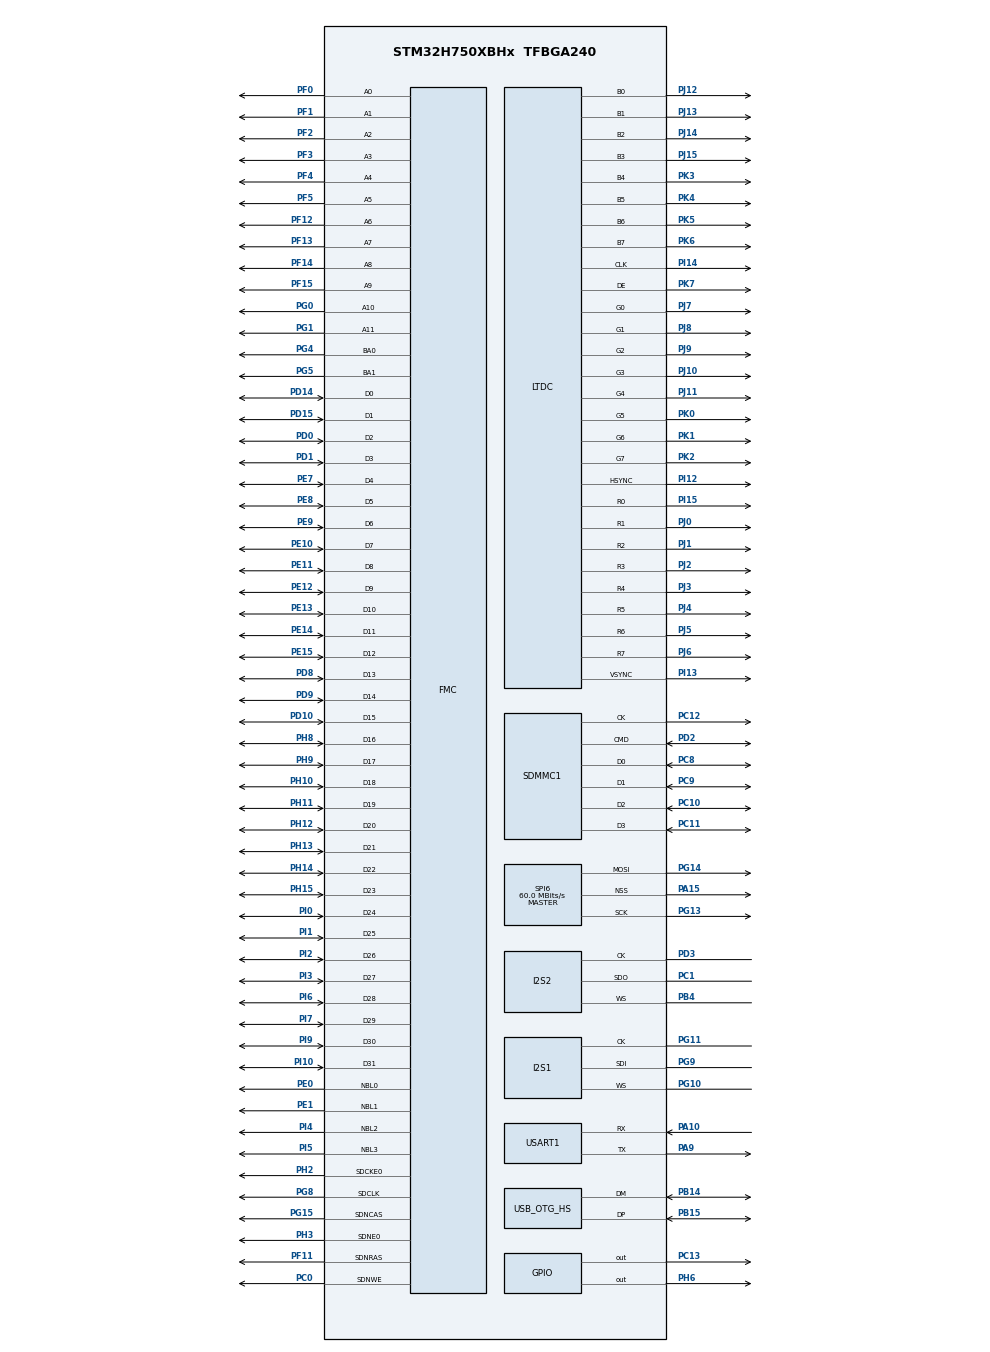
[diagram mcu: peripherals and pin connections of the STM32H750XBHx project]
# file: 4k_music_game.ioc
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CORTEX_M7.AccessPermission-Cortex_Memory_Protection_Unit_Region0_Settings=MPU_REGION_FULL_ACCESS
CORTEX_M7.AccessPermission_S-Cortex_Memory_Protection_Unit_Region1_Settings_S=MPU_REGION_FULL_ACCESS
CORTEX_M7.AccessPermission_Spec=MPU_REGION_FULL_ACCESS
CORTEX_M7.BaseAddress-Cortex_Memory_Protection_Unit_Region0_Settings=0xC0000000
CORTEX_M7.BaseAddress_S-Cortex_Memory_Protection_Unit_Region1_Settings_S=0x90000000
CORTEX_M7.BaseAddress_Spec=0xC0000000
CORTEX_M7.CPU_DCache=Enabled
CORTEX_M7.CPU_ICache=Enabled
CORTEX_M7.DisableExec_Spec=MPU_INSTRUCTION_ACCESS_ENABLE
CORTEX_M7.Enable-Cortex_Memory_Protection_Unit_Region0_Settings=MPU_REGION_ENABLE
CORTEX_M7.Enable_S-Cortex_Memory_Protection_Unit_Region1_Settings_S=MPU_REGION_ENABLE
CORTEX_M7.Enable_Spec=MPU_REGION_ENABLE
CORTEX_M7.IsBufferable-Cortex_Memory_Protection_Unit_Region0_Settings=MPU_ACCESS_BUFFERABLE
CORTEX_M7.IsBufferable_Spec=MPU_ACCESS_NOT_BUFFERABLE
CORTEX_M7.IsCacheable-Cortex_Memory_Protection_Unit_Region0_Settings=MPU_ACCESS_CACHEABLE
CORTEX_M7.IsCacheable_S-Cortex_Memory_Protection_Unit_Region1_Settings_S=MPU_ACCESS_CACHEABLE
CORTEX_M7.IsCacheable_Spec=MPU_ACCESS_CACHEABLE
CORTEX_M7.IsShareable_Spec=MPU_ACCESS_NOT_SHAREABLE
CORTEX_M7.MPU_Control=MPU_PRIVILEGED_DEFAULT
CORTEX_M7.Size-Cortex_Memory_Protection_Unit_Region0_Settings=MPU_REGION_SIZE_16MB
CORTEX_M7.Size_S-Cortex_Memory_Protection_Unit_Region1_Settings_S=MPU_REGION_SIZE_32MB
CORTEX_M7.Size_Spec=MPU_REGION_SIZE_16MB
CORTEX_M7.SubRegionDisable_Spec=0x0
CORTEX_M7.default_mode_Activation=1
DMA2D.ColorMode=DMA2D_OUTPUT_RGB565
DMA2D.Mode=DMA2D_M2M
Dma.Request0=SPI1_RX
Dma.Request1=SPI2_TX
Dma.SPI1_RX.0.Direction=DMA_PERIPH_TO_MEMORY
Dma.SPI1_RX.0.EventEnable=DISABLE
Dma.SPI1_RX.0.FIFOMode=DMA_FIFOMODE_DISABLE
Dma.SPI1_RX.0.Instance=DMA1_Stream0
Dma.SPI1_RX.0.MemDataAlignment=DMA_MDATAALIGN_WORD
Dma.SPI1_RX.0.MemInc=DMA_MINC_ENABLE
Dma.SPI1_RX.0.Mode=DMA_CIRCULAR
Dma.SPI1_RX.0.PeriphDataAlignment=DMA_PDATAALIGN_WORD
Dma.SPI1_RX.0.PeriphInc=DMA_PINC_DISABLE
Dma.SPI1_RX.0.Polarity=HAL_DMAMUX_REQ_GEN_RISING
Dma.SPI1_RX.0.Priority=DMA_PRIORITY_HIGH
Dma.SPI1_RX.0.RequestNumber=1
Dma.SPI1_RX.0.SignalID=NONE
Dma.SPI1_RX.0.SyncEnable=DISABLE
Dma.SPI1_RX.0.SyncPolarity=HAL_DMAMUX_SYNC_NO_EVENT
Dma.SPI1_RX.0.SyncRequestNumber=1
Dma.SPI1_RX.0.SyncSignalID=NONE
Dma.SPI2_TX.1.Direction=DMA_MEMORY_TO_PERIPH
Dma.SPI2_TX.1.EventEnable=DISABLE
Dma.SPI2_TX.1.FIFOMode=DMA_FIFOMODE_DISABLE
Dma.SPI2_TX.1.Instance=DMA1_Stream1
Dma.SPI2_TX.1.MemDataAlignment=DMA_MDATAALIGN_HALFWORD
Dma.SPI2_TX.1.MemInc=DMA_MINC_ENABLE
Dma.SPI2_TX.1.Mode=DMA_CIRCULAR
Dma.SPI2_TX.1.PeriphDataAlignment=DMA_PDATAALIGN_HALFWORD
Dma.SPI2_TX.1.PeriphInc=DMA_PINC_DISABLE
Dma.SPI2_TX.1.Polarity=HAL_DMAMUX_REQ_GEN_RISING
Dma.SPI2_TX.1.Priority=DMA_PRIORITY_LOW
Dma.SPI2_TX.1.RequestNumber=1
Dma.SPI2_TX.1.SignalID=NONE
Dma.SPI2_TX.1.SyncEnable=DISABLE
Dma.SPI2_TX.1.SyncPolarity=HAL_DMAMUX_SYNC_NO_EVENT
Dma.SPI2_TX.1.SyncRequestNumber=1
Dma.SPI2_TX.1.SyncSignalID=NONE
FMC.CASLatency1=FMC_SDRAM_CAS_LATENCY_3
FMC.ExitSelfRefreshDelay1=7
FMC.LoadToActiveDelay1=2
FMC.RCDDelay1=2
FMC.RPDelay1=2
FMC.RPDelay2=2
FMC.ReadBurst1=FMC_SDRAM_RBURST_ENABLE
FMC.ReadBurst2=FMC_SDRAM_RBURST_ENABLE
FMC.RowCycleDelay1=7
FMC.RowCycleDelay2=7
FMC.SDClockPeriod1=FMC_SDRAM_CLOCK_PERIOD_2
FMC.SDClockPeriod2=FMC_SDRAM_CLOCK_PERIOD_2
FMC.SelfRefreshTime1=4
FMC.WriteRecoveryTime1=3
FREERTOS.Tasks01=defaultTask,24,256,StartDefaultTask,Default,NULL,Dynamic,NULL,NULL
FREERTOS.configCHECK_FOR_STACK_OVERFLOW=2
FREERTOS.configENABLE_FPU=1
FREERTOS.configGENERATE_RUN_TIME_STATS=1
FREERTOS.configTOTAL_HEAP_SIZE=256000
FREERTOS.configUSE_STATS_FORMATTING_FUNCTIONS=1
FREERTOS.configUSE_TICK_HOOK=1
I2S1.AudioFreq=I2S_AUDIOFREQ_32K
I2S1.Data24BitAlignment=I2S_DATA_24BIT_ALIGNMENT_RIGHT
I2S1.DataFormat=I2S_DATAFORMAT_24B
I2S1.ErrorAudioFreq=-0.26 %
I2S1.Instance=SPI$Index
I2S1.RealAudioFreq=31.914 KHz
I2S2.AudioFreq=I2S_AUDIOFREQ_44K
I2S2.ErrorAudioFreq=0.26 %
I2S2.Instance=SPI$Index
I2S2.RealAudioFreq=44.117 KHz
JPEG.JPEG_RGB_FORMAT=JPEG_RGB565
LTDC.ActiveW=800
LTDC.Alpha0_L0=0
LTDC.Alpha0_L1=122
LTDC.Alpha_L0=255
LTDC.FBStartAdress_L0=0xC0000000
LTDC.Green_L0=255
LTDC.HBP=80
LTDC.HFP=200
LTDC.HSync=1
LTDC.ImageHeight_L0=480
LTDC.ImageWidth_L0=800
LTDC.Layers=0
LTDC.PixelFormat_L0=LTDC_PIXEL_FORMAT_RGB565
LTDC.Red_L1=255
LTDC.VBP=40
LTDC.VFP=22
LTDC.VSync=1
LTDC.WindowX1_L0=800
LTDC.WindowX1_L1=800
LTDC.WindowY1_L0=480
LTDC.WindowY1_L1=480
Mcu.Family=STM32H7
Mcu.Name=STM32H750XBHx
Mcu.Package=TFBGA240
Mdma.MDMA_Channel6.JPEG_OUTFIFO_TH.0.BlockCount=0
Mdma.MDMA_Channel6.JPEG_OUTFIFO_TH.0.BlockDataLength=0
Mdma.MDMA_Channel6.JPEG_OUTFIFO_TH.0.BufferTransferLength=32
Mdma.MDMA_Channel6.JPEG_OUTFIFO_TH.0.CircularMode=MDMA_LINEAR_LIST
Mdma.MDMA_Channel6.JPEG_OUTFIFO_TH.0.DataAlignment=MDMA_DATAALIGN_PACKENABLE
Mdma.MDMA_Channel6.JPEG_OUTFIFO_TH.0.DestBlockAddressOffset=0
Mdma.MDMA_Channel6.JPEG_OUTFIFO_TH.0.DestBurst=MDMA_DEST_BURST_32BEATS
Mdma.MDMA_Channel6.JPEG_OUTFIFO_TH.0.DestDataSize=MDMA_DEST_DATASIZE_WORD
Mdma.MDMA_Channel6.JPEG_OUTFIFO_TH.0.DestinationInc=MDMA_DEST_INC_WORD
Mdma.MDMA_Channel6.JPEG_OUTFIFO_TH.0.DstAddress=0
Mdma.MDMA_Channel6.JPEG_OUTFIFO_TH.0.Endianness=MDMA_LITTLE_ENDIANNESS_PRESERVE
Mdma.MDMA_Channel6.JPEG_OUTFIFO_TH.0.Instance=MDMA_Channel6
Mdma.MDMA_Channel6.JPEG_OUTFIFO_TH.0.MaskAddress=0
Mdma.MDMA_Channel6.JPEG_OUTFIFO_TH.0.MaskData=0
Mdma.MDMA_Channel6.JPEG_OUTFIFO_TH.0.Priority=MDMA_PRIORITY_VERY_HIGH
Mdma.MDMA_Channel6.JPEG_OUTFIFO_TH.0.Rank=First
Mdma.MDMA_Channel6.JPEG_OUTFIFO_TH.0.SourceBlockAddressOffset=0
Mdma.MDMA_Channel6.JPEG_OUTFIFO_TH.0.SourceBurst=MDMA_SOURCE_BURST_32BEATS
Mdma.MDMA_Channel6.JPEG_OUTFIFO_TH.0.SourceDataSize=MDMA_SRC_DATASIZE_WORD
Mdma.MDMA_Channel6.JPEG_OUTFIFO_TH.0.SourceInc=MDMA_SRC_INC_DISABLE
Mdma.MDMA_Channel6.JPEG_OUTFIFO_TH.0.SrcAddress=0
Mdma.MDMA_Channel6.JPEG_OUTFIFO_TH.0.TransferTriggerMode=MDMA_BUFFER_TRANSFER
Mdma.MDMA_Channel6.Request0=JPEG_OUTFIFO_TH
Mdma.MDMA_Channel6.RequestsNb=1
Mdma.MDMA_Channel7.JPEG_INFIFO_TH.0.BlockCount=0
Mdma.MDMA_Channel7.JPEG_INFIFO_TH.0.BlockDataLength=0
Mdma.MDMA_Channel7.JPEG_INFIFO_TH.0.BufferTransferLength=32
Mdma.MDMA_Channel7.JPEG_INFIFO_TH.0.CircularMode=MDMA_LINEAR_LIST
Mdma.MDMA_Channel7.JPEG_INFIFO_TH.0.DataAlignment=MDMA_DATAALIGN_PACKENABLE
Mdma.MDMA_Channel7.JPEG_INFIFO_TH.0.DestBlockAddressOffset=0
Mdma.MDMA_Channel7.JPEG_INFIFO_TH.0.DestBurst=MDMA_DEST_BURST_32BEATS
Mdma.MDMA_Channel7.JPEG_INFIFO_TH.0.DestDataSize=MDMA_DEST_DATASIZE_WORD
Mdma.MDMA_Channel7.JPEG_INFIFO_TH.0.DestinationInc=MDMA_DEST_INC_DISABLE
Mdma.MDMA_Channel7.JPEG_INFIFO_TH.0.DstAddress=0
Mdma.MDMA_Channel7.JPEG_INFIFO_TH.0.Endianness=MDMA_LITTLE_ENDIANNESS_PRESERVE
Mdma.MDMA_Channel7.JPEG_INFIFO_TH.0.Instance=MDMA_Channel7
Mdma.MDMA_Channel7.JPEG_INFIFO_TH.0.MaskAddress=0
Mdma.MDMA_Channel7.JPEG_INFIFO_TH.0.MaskData=0
Mdma.MDMA_Channel7.JPEG_INFIFO_TH.0.Priority=MDMA_PRIORITY_HIGH
Mdma.MDMA_Channel7.JPEG_INFIFO_TH.0.Rank=First
Mdma.MDMA_Channel7.JPEG_INFIFO_TH.0.SourceBlockAddressOffset=0
Mdma.MDMA_Channel7.JPEG_INFIFO_TH.0.SourceBurst=MDMA_SOURCE_BURST_32BEATS
Mdma.MDMA_Channel7.JPEG_INFIFO_TH.0.SourceDataSize=MDMA_SRC_DATASIZE_WORD
Mdma.MDMA_Channel7.JPEG_INFIFO_TH.0.SourceInc=MDMA_SRC_INC_WORD
Mdma.MDMA_Channel7.JPEG_INFIFO_TH.0.SrcAddress=0
Mdma.MDMA_Channel7.JPEG_INFIFO_TH.0.TransferTriggerMode=MDMA_BUFFER_TRANSFER
Mdma.MDMA_Channel7.Request0=JPEG_INFIFO_TH
Mdma.MDMA_Channel7.RequestsNb=1
Mdma.RequestSet0=MDMA_Channel7
Mdma.RequestSet1=MDMA_Channel6
Mdma.RequestSetsNb=2
NVIC.DMA1_Stream0_IRQn=true\:5\:0\:false\:false\:true\:true\:false\:true\:true
NVIC.DMA1_Stream1_IRQn=true\:5\:0\:false\:false\:true\:true\:false\:true\:true
NVIC.JPEG_IRQn=true\:5\:0\:false\:false\:true\:true\:true\:true\:true
NVIC.LTDC_ER_IRQn=true\:5\:0\:false\:false\:true\:true\:true\:true\:true
NVIC.LTDC_IRQn=true\:5\:0\:false\:false\:true\:true\:true\:true\:true
NVIC.MDMA_IRQn=true\:5\:0\:false\:false\:true\:true\:false\:true\:true
NVIC.OTG_HS_EP1_IN_IRQn=true\:5\:0\:false\:false\:true\:true\:true\:true\:true
NVIC.OTG_HS_EP1_OUT_IRQn=true\:5\:0\:false\:false\:true\:true\:true\:true\:true
NVIC.OTG_HS_IRQn=true\:5\:0\:false\:false\:true\:true\:true\:true\:true
NVIC.PriorityGroup=NVIC_PRIORITYGROUP_4
NVIC.SDMMC1_IRQn=true\:5\:0\:false\:false\:true\:true\:true\:true\:true
NVIC.TIM17_IRQn=true\:15\:0\:false\:false\:true\:false\:false\:true\:true
NVIC.TimeBase=TIM17_IRQn
NVIC.TimeBaseIP=TIM17
PA10.GPIO_Speed=GPIO_SPEED_FREQ_VERY_HIGH
PA10.Mode=Asynchronous
PA10.Signal=USART1_RX
PA13\ (JTMS/SWDIO).Mode=Serial_Wire
PA13\ (JTMS/SWDIO).Signal=DEBUG_JTMS-SWDIO
PA14\ (JTCK/SWCLK).Mode=Serial_Wire
PA14\ (JTCK/SWCLK).Signal=DEBUG_JTCK-SWCLK
PA15\ (JTDI).GPIO_Speed=GPIO_SPEED_FREQ_VERY_HIGH
PA15\ (JTDI).Mode=NSS_Signal_Hard_Output
PA15\ (JTDI).Signal=SPI6_NSS
PA9.GPIO_Speed=GPIO_SPEED_FREQ_VERY_HIGH
PA9.Mode=Asynchronous
PA9.Signal=USART1_TX
PB14.GPIO_Speed=GPIO_SPEED_FREQ_VERY_HIGH
PB14.Mode=Host_FS
PB14.Signal=USB_OTG_HS_DM
PB15.GPIO_Speed=GPIO_SPEED_FREQ_VERY_HIGH
PB15.Mode=Host_FS
PB15.Signal=USB_OTG_HS_DP
PB4\ (NJTRST).GPIO_Speed=GPIO_SPEED_FREQ_VERY_HIGH
PB4\ (NJTRST).Mode=Half_Duplex_Master_Tx
PB4\ (NJTRST).Signal=I2S2_WS
PC0.Signal=FMC_SDNWE
PC1.GPIO_Speed=GPIO_SPEED_FREQ_VERY_HIGH
PC1.Mode=Half_Duplex_Master_Tx
PC1.Signal=I2S2_SDO
PC10.Mode=SD_4_bits_Wide_bus
PC10.Signal=SDMMC1_D2
PC11.Mode=SD_4_bits_Wide_bus
PC11.Signal=SDMMC1_D3
PC12.Mode=SD_4_bits_Wide_bus
PC12.Signal=SDMMC1_CK
PC13.Signal=GPIO_Output
PC14-OSC32_IN\ (OSC32_IN).Mode=LSE-External-Oscillator
PC14-OSC32_IN\ (OSC32_IN).Signal=RCC_OSC32_IN
PC15-OSC32_OUT\ (OSC32_OUT).Mode=LSE-External-Oscillator
PC15-OSC32_OUT\ (OSC32_OUT).Signal=RCC_OSC32_OUT
PC8.Mode=SD_4_bits_Wide_bus
PC8.Signal=SDMMC1_D0
PC9.Mode=SD_4_bits_Wide_bus
PC9.Signal=SDMMC1_D1
PD0.Signal=FMC_D2_DA2
PD1.Signal=FMC_D3_DA3
PD10.Signal=FMC_D15_DA15
PD14.Signal=FMC_D0_DA0
PD15.Signal=FMC_D1_DA1
PD2.Mode=SD_4_bits_Wide_bus
PD2.Signal=SDMMC1_CMD
PD3.GPIO_Speed=GPIO_SPEED_FREQ_VERY_HIGH
PD3.Mode=Half_Duplex_Master_Tx
PD3.Signal=I2S2_CK
PD8.Signal=FMC_D13_DA13
PD9.Signal=FMC_D14_DA14
PE0.Signal=FMC_NBL0
PE1.Signal=FMC_NBL1
PE10.Signal=FMC_D7_DA7
PE11.Signal=FMC_D8_DA8
PE12.Signal=FMC_D9_DA9
PE13.Signal=FMC_D10_DA10
PE14.Signal=FMC_D11_DA11
PE15.Signal=FMC_D12_DA12
PE7.Signal=FMC_D4_DA4
PE8.Signal=FMC_D5_DA5
PE9.Signal=FMC_D6_DA6
PF0.Signal=FMC_A0
PF1.Signal=FMC_A1
PF11.Signal=FMC_SDNRAS
PF12.Signal=FMC_A6
PF13.Signal=FMC_A7
PF14.Signal=FMC_A8
PF15.Signal=FMC_A9
PF2.Signal=FMC_A2
PF3.Signal=FMC_A3
PF4.Signal=FMC_A4
PF5.Signal=FMC_A5
PG0.Signal=FMC_A10
PG1.Signal=FMC_A11
PG10.GPIO_Speed=GPIO_SPEED_FREQ_VERY_HIGH
PG10.Mode=Half_Duplex_Master_Rx
PG10.Signal=I2S1_WS
PG11.GPIO_Speed=GPIO_SPEED_FREQ_VERY_HIGH
PG11.Mode=Half_Duplex_Master_Rx
PG11.Signal=I2S1_CK
PG13.GPIO_Speed=GPIO_SPEED_FREQ_VERY_HIGH
PG13.Mode=TX_Only_Simplex_Unidirect_Master
PG13.Signal=SPI6_SCK
PG14.GPIO_Speed=GPIO_SPEED_FREQ_VERY_HIGH
PG14.Mode=TX_Only_Simplex_Unidirect_Master
PG14.Signal=SPI6_MOSI
PG15.Signal=FMC_SDNCAS
PG4.Signal=FMC_A14_BA0
PG5.Signal=FMC_A15_BA1
PG8.Signal=FMC_SDCLK
PG9.GPIO_Speed=GPIO_SPEED_FREQ_VERY_HIGH
PG9.Mode=Half_Duplex_Master_Rx
PG9.Signal=I2S1_SDI
PH0-OSC_IN\ (PH0).Mode=HSE-External-Oscillator
PH0-OSC_IN\ (PH0).Signal=RCC_OSC_IN
PH1-OSC_OUT\ (PH1).Mode=HSE-External-Oscillator
PH1-OSC_OUT\ (PH1).Signal=RCC_OSC_OUT
PH10.Signal=FMC_D18
PH11.Signal=FMC_D19
PH12.Signal=FMC_D20
PH13.Signal=FMC_D21
PH14.Signal=FMC_D22
PH15.Signal=FMC_D23
PH2.Mode=SdramChipSelect1_1
PH2.Signal=FMC_SDCKE0
PH3.Mode=SdramChipSelect1_1
PH3.Signal=FMC_SDNE0
PH6.PinState=GPIO_PIN_SET
PH6.Signal=GPIO_Output
PH8.Signal=FMC_D16
PH9.Signal=FMC_D17
PI0.Signal=FMC_D24
PI1.Signal=FMC_D25
PI10.Signal=FMC_D31
PI12.GPIO_Speed=GPIO_SPEED_FREQ_VERY_HIGH
PI12.Mode=RGB888
PI12.Signal=LTDC_HSYNC
PI13.GPIO_Speed=GPIO_SPEED_FREQ_VERY_HIGH
PI13.Mode=RGB888
PI13.Signal=LTDC_VSYNC
PI14.GPIO_Speed=GPIO_SPEED_FREQ_VERY_HIGH
PI14.Mode=RGB888
PI14.Signal=LTDC_CLK
PI15.GPIO_Speed=GPIO_SPEED_FREQ_VERY_HIGH
PI15.Mode=RGB888
PI15.Signal=LTDC_R0
PI2.Signal=FMC_D26
PI3.Signal=FMC_D27
PI4.Signal=FMC_NBL2
PI5.Signal=FMC_NBL3
PI6.Signal=FMC_D28
PI7.Signal=FMC_D29
PI9.Signal=FMC_D30
PJ0.GPIO_Speed=GPIO_SPEED_FREQ_VERY_HIGH
PJ0.Mode=RGB888
PJ0.Signal=LTDC_R1
PJ1.GPIO_Speed=GPIO_SPEED_FREQ_VERY_HIGH
PJ1.Mode=RGB888
PJ1.Signal=LTDC_R2
PJ10.GPIO_Speed=GPIO_SPEED_FREQ_VERY_HIGH
PJ10.Mode=RGB888
PJ10.Signal=LTDC_G3
PJ11.GPIO_Speed=GPIO_SPEED_FREQ_VERY_HIGH
PJ11.Mode=RGB888
PJ11.Signal=LTDC_G4
PJ12.GPIO_Speed=GPIO_SPEED_FREQ_VERY_HIGH
PJ12.Mode=RGB888
PJ12.Signal=LTDC_B0
PJ13.GPIO_Speed=GPIO_SPEED_FREQ_VERY_HIGH
PJ13.Mode=RGB888
PJ13.Signal=LTDC_B1
PJ14.GPIO_Speed=GPIO_SPEED_FREQ_VERY_HIGH
PJ14.Mode=RGB888
PJ14.Signal=LTDC_B2
PJ15.GPIO_Speed=GPIO_SPEED_FREQ_VERY_HIGH
PJ15.Mode=RGB888
PJ15.Signal=LTDC_B3
PJ2.GPIO_Speed=GPIO_SPEED_FREQ_VERY_HIGH
PJ2.Mode=RGB888
PJ2.Signal=LTDC_R3
PJ3.GPIO_Speed=GPIO_SPEED_FREQ_VERY_HIGH
PJ3.Mode=RGB888
PJ3.Signal=LTDC_R4
PJ4.GPIO_Speed=GPIO_SPEED_FREQ_VERY_HIGH
PJ4.Mode=RGB888
PJ4.Signal=LTDC_R5
PJ5.GPIO_Speed=GPIO_SPEED_FREQ_VERY_HIGH
PJ5.Mode=RGB888
PJ5.Signal=LTDC_R6
PJ6.GPIO_Speed=GPIO_SPEED_FREQ_VERY_HIGH
PJ6.Mode=RGB888
PJ6.Signal=LTDC_R7
PJ7.GPIO_Speed=GPIO_SPEED_FREQ_VERY_HIGH
PJ7.Mode=RGB888
PJ7.Signal=LTDC_G0
PJ8.GPIO_Speed=GPIO_SPEED_FREQ_VERY_HIGH
PJ8.Mode=RGB888
PJ8.Signal=LTDC_G1
PJ9.GPIO_Speed=GPIO_SPEED_FREQ_VERY_HIGH
PJ9.Mode=RGB888
PJ9.Signal=LTDC_G2
PK0.GPIO_Speed=GPIO_SPEED_FREQ_VERY_HIGH
PK0.Mode=RGB888
PK0.Signal=LTDC_G5
PK1.GPIO_Speed=GPIO_SPEED_FREQ_VERY_HIGH
PK1.Mode=RGB888
PK1.Signal=LTDC_G6
PK2.GPIO_Speed=GPIO_SPEED_FREQ_VERY_HIGH
PK2.Mode=RGB888
PK2.Signal=LTDC_G7
PK3.GPIO_Speed=GPIO_SPEED_FREQ_VERY_HIGH
PK3.Mode=RGB888
PK3.Signal=LTDC_B4
PK4.GPIO_Speed=GPIO_SPEED_FREQ_VERY_HIGH
PK4.Mode=RGB888
PK4.Signal=LTDC_B5
PK5.GPIO_Speed=GPIO_SPEED_FREQ_VERY_HIGH
PK5.Mode=RGB888
PK5.Signal=LTDC_B6
PK6.GPIO_Speed=GPIO_SPEED_FREQ_VERY_HIGH
PK6.Mode=RGB888
PK6.Signal=LTDC_B7
PK7.GPIO_Speed=GPIO_SPEED_FREQ_VERY_HIGH
PK7.Mode=RGB888
PK7.Signal=LTDC_DE
ProjectManager.HeapSize=0x1000
ProjectManager.StackSize=0x1000
ProjectManager.TargetToolchain=CMake
RCC.ADCFreq_Value=275000000
RCC.APB1Freq_Value=120000000
RCC.APB2Freq_Value=120000000
RCC.APB3Freq_Value=120000000
RCC.APB4Freq_Value=120000000
RCC.CKPERSourceSelection=RCC_CLKPSOURCE_HSE
RCC.CortexFreq_Value=480000000
RCC.D1PPRE=RCC_APB3_DIV2
RCC.D2PPRE1=RCC_APB1_DIV2
RCC.D2PPRE2=RCC_APB2_DIV2
RCC.D3PPRE=RCC_APB4_DIV2
RCC.DIVM1=5
RCC.DIVM2=5
RCC.DIVM3=1
RCC.DIVN1=192
RCC.DIVN2=110
RCC.DIVN3=6
RCC.DIVQ1=5
RCC.DIVR3=5
RCC.HCLKFreq_Value=240000000
RCC.HPRE=RCC_HCLK_DIV2
RCC.PLL2FRACN=0
RCC.PLL3FRACN=0
RCC.PLLFRACN=0
RCC.PLLSourceVirtual=RCC_PLLSOURCE_HSE
RCC.SYSCLKFreq_VALUE=480000000
RCC.SYSCLKSource=RCC_SYSCLKSOURCE_PLLCLK
RCC.USBCLockSelection=RCC_USBCLKSOURCE_HSI48
RCC.USBFreq_Value=48000000
SDMMC1.ClockDiv=6
SDMMC1.HardwareFlowControl=SDMMC_HARDWARE_FLOW_CONTROL_ENABLE
SH.FMC_A0.0=FMC_A0,12b-sda1
SH.FMC_A1.0=FMC_A1,12b-sda1
SH.FMC_A10.0=FMC_A10,12b-sda1
SH.FMC_A11.0=FMC_A11,12b-sda1
SH.FMC_A14_BA0.0=FMC_BA0,FourSdramBanks1
SH.FMC_A15_BA1.0=FMC_BA1,FourSdramBanks1
SH.FMC_A2.0=FMC_A2,12b-sda1
SH.FMC_A3.0=FMC_A3,12b-sda1
SH.FMC_A4.0=FMC_A4,12b-sda1
SH.FMC_A5.0=FMC_A5,12b-sda1
SH.FMC_A6.0=FMC_A6,12b-sda1
SH.FMC_A7.0=FMC_A7,12b-sda1
SH.FMC_A8.0=FMC_A8,12b-sda1
SH.FMC_A9.0=FMC_A9,12b-sda1
SH.FMC_D0_DA0.0=FMC_D0,sd-32b-d1
SH.FMC_D10_DA10.0=FMC_D10,sd-32b-d1
SH.FMC_D11_DA11.0=FMC_D11,sd-32b-d1
SH.FMC_D12_DA12.0=FMC_D12,sd-32b-d1
SH.FMC_D13_DA13.0=FMC_D13,sd-32b-d1
SH.FMC_D14_DA14.0=FMC_D14,sd-32b-d1
SH.FMC_D15_DA15.0=FMC_D15,sd-32b-d1
SH.FMC_D16.0=FMC_D16,sd-32b-d1
SH.FMC_D17.0=FMC_D17,sd-32b-d1
SH.FMC_D18.0=FMC_D18,sd-32b-d1
SH.FMC_D19.0=FMC_D19,sd-32b-d1
SH.FMC_D1_DA1.0=FMC_D1,sd-32b-d1
SH.FMC_D20.0=FMC_D20,sd-32b-d1
SH.FMC_D21.0=FMC_D21,sd-32b-d1
SH.FMC_D22.0=FMC_D22,sd-32b-d1
SH.FMC_D23.0=FMC_D23,sd-32b-d1
SH.FMC_D24.0=FMC_D24,sd-32b-d1
SH.FMC_D25.0=FMC_D25,sd-32b-d1
SH.FMC_D26.0=FMC_D26,sd-32b-d1
SH.FMC_D27.0=FMC_D27,sd-32b-d1
SH.FMC_D28.0=FMC_D28,sd-32b-d1
SH.FMC_D29.0=FMC_D29,sd-32b-d1
SH.FMC_D2_DA2.0=FMC_D2,sd-32b-d1
SH.FMC_D30.0=FMC_D30,sd-32b-d1
SH.FMC_D31.0=FMC_D31,sd-32b-d1
SH.FMC_D3_DA3.0=FMC_D3,sd-32b-d1
SH.FMC_D4_DA4.0=FMC_D4,sd-32b-d1
SH.FMC_D5_DA5.0=FMC_D5,sd-32b-d1
SH.FMC_D6_DA6.0=FMC_D6,sd-32b-d1
SH.FMC_D7_DA7.0=FMC_D7,sd-32b-d1
SH.FMC_D8_DA8.0=FMC_D8,sd-32b-d1
SH.FMC_D9_DA9.0=FMC_D9,sd-32b-d1
SH.FMC_NBL0.0=FMC_NBL0,Sd4ByteEnable1
SH.FMC_NBL1.0=FMC_NBL1,Sd4ByteEnable1
SH.FMC_NBL2.0=FMC_NBL2,Sd4ByteEnable1
SH.FMC_NBL3.0=FMC_NBL3,Sd4ByteEnable1
SH.FMC_SDCLK.0=FMC_SDCLK,12b-sda1
SH.FMC_SDNCAS.0=FMC_SDNCAS,12b-sda1
SH.FMC_SDNRAS.0=FMC_SDNRAS,12b-sda1
SH.FMC_SDNWE.0=FMC_SDNWE,12b-sda1
SPI6.CalculateBaudRate=60.0 MBits/s
SPI6.DataSize=SPI_DATASIZE_8BIT
SPI6.Direction=SPI_DIRECTION_2LINES_TXONLY
SPI6.FifoThreshold=SPI_FIFO_THRESHOLD_02DATA
SPI6.Mode=SPI_MODE_MASTER
SPI6.VirtualNSS=VM_NSSHARD
SPI6.VirtualType=VM_MASTER
USART1.VirtualMode-Asynchronous=VM_ASYNC
USB_OTG_HS.VirtualMode-Host_FS=Host_FS
VP_DMA2D_VS_DMA2D.Mode=DMA2D_Activate
VP_FREERTOS_VS_CMSIS_V2.Mode=CMSIS_V2
VP_JPEG_VS_JPEG.Mode=JPEG_Activate
VP_MEMORYMAP_VS_MEMORYMAP.Mode=CurAppReg
VP_SYS_VS_tim17.Mode=TIM17
board=custom

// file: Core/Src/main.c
/* USER CODE BEGIN Header */
/**
  ******************************************************************************
  * @file           : main.c
  * @brief          : Main program body
  ******************************************************************************
  * @attention
  *
  * Copyright (c) 2025 STMicroelectronics.
  * All rights reserved.
  *
  * This software is licensed under terms that can be found in the LICENSE file
  * in the root directory of this software component.
  * If no LICENSE file comes with this software, it is provided AS-IS.
  *
  ******************************************************************************
  */
/* USER CODE END Header */
#include "main.h"
#include "cmsis_os.h"
#include "dma.h"
#include "dma2d.h"
#include "i2s.h"
#include "jpeg.h"
#include "ltdc.h"
#include "mdma.h"
#include "memorymap.h"
#include "sdmmc.h"
#include "spi.h"
#include "usart.h"
#include "usb_otg.h"
#include "gpio.h"
#include "fmc.h"

/* USER CODE BEGIN Includes */
#include "init.h"
/* USER CODE END Includes */

void SystemClock_Config(void);
static void MPU_Config(void);
void MX_FREERTOS_Init(void);

int main(void)
{

  /* MPU Configuration--------------------------------------------------------*/
  MPU_Config();

  /* Enable the CPU Cache */

  /* Enable I-Cache---------------------------------------------------------*/
  SCB_EnableICache();

  /* Enable D-Cache---------------------------------------------------------*/
  SCB_EnableDCache();

  /* MCU Configuration--------------------------------------------------------*/

  /* Reset of all peripherals, Initializes the Flash interface and the Systick. */
  HAL_Init();

  /* Configure the system clock */
  SystemClock_Config();

  /* Initialize all configured peripherals */
  MX_GPIO_Init();
  MX_DMA_Init();
  MX_MDMA_Init();
  MX_SPI6_Init();
  MX_I2S1_Init();
  MX_SDMMC1_SD_Init();
  MX_FMC_Init();
  MX_DMA2D_Init();
  MX_JPEG_Init();
  MX_LTDC_Init();
  MX_I2S2_Init();
  MX_USB_OTG_HS_HCD_Init();
  MX_USART1_UART_Init();
  /* USER CODE BEGIN 2 */
  init_all();
  /* USER CODE END 2 */

  /* Init scheduler */
  osKernelInitialize();

  /* Call init function for freertos objects (in cmsis_os2.c) */
  MX_FREERTOS_Init();

  /* Start scheduler */
  osKernelStart();

  /* We should never get here as control is now taken by the scheduler */

  /* Infinite loop */
  while (1)
  {

  }
}

void SystemClock_Config(void)
{
  RCC_OscInitTypeDef RCC_OscInitStruct = {0};
  RCC_ClkInitTypeDef RCC_ClkInitStruct = {0};

  /** Supply configuration update enable
  */
  HAL_PWREx_ConfigSupply(PWR_LDO_SUPPLY);

  /** Configure the main internal regulator output voltage
  */
  __HAL_PWR_VOLTAGESCALING_CONFIG(PWR_REGULATOR_VOLTAGE_SCALE0);

  while(!__HAL_PWR_GET_FLAG(PWR_FLAG_VOSRDY)) {}

  /** Initializes the RCC Oscillators according to the specified parameters
  * in the RCC_OscInitTypeDef structure.
  */
  RCC_OscInitStruct.OscillatorType = RCC_OSCILLATORTYPE_HSI48|RCC_OSCILLATORTYPE_HSE;
  RCC_OscInitStruct.HSEState = RCC_HSE_ON;
  RCC_OscInitStruct.HSI48State = RCC_HSI48_ON;
  RCC_OscInitStruct.PLL.PLLState = RCC_PLL_ON;
  RCC_OscInitStruct.PLL.PLLSource = RCC_PLLSOURCE_HSE;
  RCC_OscInitStruct.PLL.PLLM = 5;
  RCC_OscInitStruct.PLL.PLLN = 192;
  RCC_OscInitStruct.PLL.PLLP = 2;
  RCC_OscInitStruct.PLL.PLLQ = 5;
  RCC_OscInitStruct.PLL.PLLR = 2;
  RCC_OscInitStruct.PLL.PLLRGE = RCC_PLL1VCIRANGE_2;
  RCC_OscInitStruct.PLL.PLLVCOSEL = RCC_PLL1VCOWIDE;
  RCC_OscInitStruct.PLL.PLLFRACN = 0;
  if (HAL_RCC_OscConfig(&RCC_OscInitStruct) != HAL_OK)
  {
    Error_Handler();
  }

  /** Initializes the CPU, AHB and APB buses clocks
  */
  RCC_ClkInitStruct.ClockType = RCC_CLOCKTYPE_HCLK|RCC_CLOCKTYPE_SYSCLK
                              |RCC_CLOCKTYPE_PCLK1|RCC_CLOCKTYPE_PCLK2
                              |RCC_CLOCKTYPE_D3PCLK1|RCC_CLOCKTYPE_D1PCLK1;
  RCC_ClkInitStruct.SYSCLKSource = RCC_SYSCLKSOURCE_PLLCLK;
  RCC_ClkInitStruct.SYSCLKDivider = RCC_SYSCLK_DIV1;
  RCC_ClkInitStruct.AHBCLKDivider = RCC_HCLK_DIV2;
  RCC_ClkInitStruct.APB3CLKDivider = RCC_APB3_DIV2;
  RCC_ClkInitStruct.APB1CLKDivider = RCC_APB1_DIV2;
  RCC_ClkInitStruct.APB2CLKDivider = RCC_APB2_DIV2;
  RCC_ClkInitStruct.APB4CLKDivider = RCC_APB4_DIV2;

  if (HAL_RCC_ClockConfig(&RCC_ClkInitStruct, FLASH_LATENCY_4) != HAL_OK)
  {
    Error_Handler();
  }
}

 /* MPU Configuration */

void MPU_Config(void)
{
  MPU_Region_InitTypeDef MPU_InitStruct = {0};

  /* Disables the MPU */
  HAL_MPU_Disable();

  /** Initializes and configures the Region and the memory to be protected
  */
  MPU_InitStruct.Enable = MPU_REGION_ENABLE;
  MPU_InitStruct.Number = MPU_REGION_NUMBER0;
  MPU_InitStruct.BaseAddress = 0xC0000000;
  MPU_InitStruct.Size = MPU_REGION_SIZE_16MB;
  MPU_InitStruct.SubRegionDisable = 0x0;
  MPU_InitStruct.TypeExtField = MPU_TEX_LEVEL0;
  MPU_InitStruct.AccessPermission = MPU_REGION_FULL_ACCESS;
  MPU_InitStruct.DisableExec = MPU_INSTRUCTION_ACCESS_ENABLE;
  MPU_InitStruct.IsShareable = MPU_ACCESS_NOT_SHAREABLE;
  MPU_InitStruct.IsCacheable = MPU_ACCESS_CACHEABLE;
  MPU_InitStruct.IsBufferable = MPU_ACCESS_NOT_BUFFERABLE;

  HAL_MPU_ConfigRegion(&MPU_InitStruct);

  /** Initializes and configures the Region and the memory to be protected
  */
  MPU_InitStruct.Number = MPU_REGION_NUMBER1;
  MPU_InitStruct.BaseAddress = 0x90000000;
  MPU_InitStruct.Size = MPU_REGION_SIZE_32MB;

  HAL_MPU_ConfigRegion(&MPU_InitStruct);
  /* Enables the MPU */
  HAL_MPU_Enable(MPU_PRIVILEGED_DEFAULT);

}

void HAL_TIM_PeriodElapsedCallback(TIM_HandleTypeDef *htim)
{
  if (htim->Instance == TIM17)
  {
    HAL_IncTick();
  }
}

void Error_Handler(void)
{
  __disable_irq();
  while (1)
  {
  }
}

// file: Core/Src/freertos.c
/* USER CODE BEGIN Header */
/**
 ******************************************************************************
 * File Name          : freertos.c
 * Description        : Code for freertos applications
 ******************************************************************************
 * @attention
 *
 * Copyright (c) 2025 STMicroelectronics.
 * All rights reserved.
 *
 * This software is licensed under terms that can be found in the LICENSE file
 * in the root directory of this software component.
 * If no LICENSE file comes with this software, it is provided AS-IS.
 *
 ******************************************************************************
 */
/* USER CODE END Header */

#include "FreeRTOS.h"
#include "task.h"
#include "main.h"
#include "cmsis_os.h"

/* USER CODE BEGIN Includes */
#include "init.h"
#include "lvgl.h"
/* USER CODE END Includes */

/* USER CODE BEGIN Variables */
/* configTOTAL_HEAP_SIZE 在 FreeRTOSConfig.h 中设置为 288000 字节 */
uint8_t ucHeap[configTOTAL_HEAP_SIZE] __attribute__((section(".ram_d2_data")));

// 移除 lvglMutex 定义，它现在在 system_task.c 中
/* USER CODE END Variables */
/* Definitions for defaultTask */
osThreadId_t defaultTaskHandle;
const osThreadAttr_t defaultTask_attributes = {
  .name = "defaultTask",
  .stack_size = 256 * 4,
  .priority = (osPriority_t) osPriorityNormal,
};

/* USER CODE BEGIN FunctionPrototypes */
// 声明外部任务函数
extern void StartSystemDisplayTask(void *argument);
extern void StartHardwareTouchTask(void *argument);

TaskHandle_t systemDisplayTaskHandle;
TaskHandle_t hardwareTouchTaskHandle;
/* USER CODE END FunctionPrototypes */

void StartDefaultTask(void *argument);

void MX_FREERTOS_Init(void); /* (MISRA C 2004 rule 8.1) */

/* Hook prototypes */
void configureTimerForRunTimeStats(void);
unsigned long getRunTimeCounterValue(void);
void vApplicationTickHook(void);
void vApplicationStackOverflowHook(xTaskHandle xTask, signed char *pcTaskName);

/* USER CODE BEGIN 1 */

/* Functions needed when configGENERATE_RUN_TIME_STATS is on */
__weak void configureTimerForRunTimeStats(void)
{
  /* 使用 SysTick 作为运行时统计的时基
     SysTick 已经配置好了，直接利用它即可 */
}

__weak unsigned long getRunTimeCounterValue(void)
{
  /* 返回当前的系统 Tick 计数
     这样每个 Tick (1ms) 增加一次 */
  return xTaskGetTickCount();
}
/* USER CODE END 1 */

/* USER CODE BEGIN 3 */
void vApplicationTickHook(void)
{
  /* This function will be called by each tick interrupt if
  configUSE_TICK_HOOK is set to 1 in FreeRTOSConfig.h. User code can be
  added here, but the tick hook is called from an interrupt context, so
  code must not attempt to block, and only the interrupt safe FreeRTOS API
  functions can be used (those that end in FromISR()). */
  lv_tick_inc(1);
}
/* USER CODE END 3 */

/* USER CODE BEGIN 4 */
void vApplicationStackOverflowHook(xTaskHandle xTask, signed char *pcTaskName)
{
  /* Run time stack overflow checking is performed if
  configCHECK_FOR_STACK_OVERFLOW is defined to 1 or 2. This hook function is
  called if a stack overflow is detected. */
}
/* USER CODE END 4 */

void MX_FREERTOS_Init(void) {

  /* USER CODE BEGIN RTOS_QUEUES */
  /* Create touch event queue */

  /* USER CODE END RTOS_QUEUES */

  /* Create the thread(s) */
  /* creation of defaultTask */
  defaultTaskHandle = osThreadNew(StartDefaultTask, NULL, &defaultTask_attributes);

  /* USER CODE BEGIN RTOS_THREADS */

  // 创建系统显示任务 (LVGL)
  xTaskCreate(StartSystemDisplayTask, "SysDispTask", 4096, NULL, tskIDLE_PRIORITY + 2, &systemDisplayTaskHandle);

  // 创建硬件触摸任务
  xTaskCreate(StartHardwareTouchTask, "HwTouchTask", 1024, NULL, tskIDLE_PRIORITY + 3, &hardwareTouchTaskHandle);

  /* USER CODE END RTOS_THREADS */

}

void StartDefaultTask(void *argument)
{
  /* USER CODE BEGIN StartDefaultTask */
  /* Infinite loop */
  for (;;)
  {
#ifdef LED_ENABLE
    LED_Toggle_All();
#endif

    /* 打印任务统计信息 */
    //     {
    //       static char pcWriteBuffer[1024];
    //       DEBUG_INFO("===== FreeRTOS Task Statistics =====");
    //       vTaskList(pcWriteBuffer);
    //       DEBUG_INFO("%s", pcWriteBuffer);

    // #if (configGENERATE_RUN_TIME_STATS == 1)
    //       DEBUG_INFO("===== Runtime Statistics =====");
    //       vTaskGetRunTimeStats(pcWriteBuffer);
    //       DEBUG_INFO("%s", pcWriteBuffer);
    // #endif

    //       DEBUG_INFO("===== Heap Info =====");
    //       DEBUG_INFO("Free Heap: %u bytes", xPortGetFreeHeapSize());
    //       DEBUG_INFO("Min Free Heap: %u bytes", xPortGetMinimumEverFreeHeapSize());
    //     }

    osDelay(3000);
  }
  /* USER CODE END StartDefaultTask */
}
